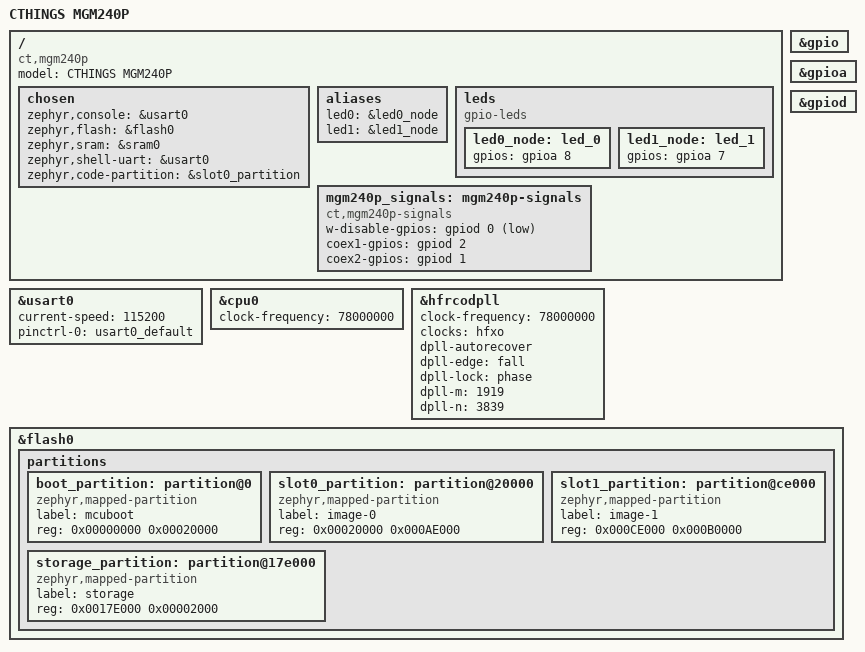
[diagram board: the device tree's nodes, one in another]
#include <silabs/xg24/mgm240pa32vnn.dtsi>
#include <zephyr/dt-bindings/gpio/gpio.h>
#include "mgm240p-pinctrl.dtsi"

/*
 * MGM240P debug interface (common to both card variants):
 *
 * PA1 - SWCLK
 * PA2 - SWDIO
 * PA3 - TRACEDATA0
 * PA4 - TRACECLK
 *
 * These pins are connected to the debug interface.
 * They are documented here but are not configured as GPIOs.
 */


/ {
	model = "CTHINGS MGM240P";
	compatible = "ct,mgm240p", "silabs,efr32mg24";

	chosen {
		zephyr,console = &usart0;
		zephyr,flash = &flash0;
		zephyr,sram = &sram0;
		zephyr,shell-uart = &usart0;
		zephyr,code-partition = &slot0_partition;
	};

	aliases {
		led0 = &led0_node;
		led1 = &led1_node;
	};

	leds {
		compatible = "gpio-leds";

		led0_node: led_0 {
			gpios = <&gpioa 8 GPIO_ACTIVE_HIGH>;
		};

		led1_node: led_1 {
			gpios = <&gpioa 7 GPIO_ACTIVE_HIGH>;
		};
	};

	mgm240p_signals: mgm240p-signals {
		compatible = "ct,mgm240p-signals";

		w-disable-gpios = <&gpiod 0 GPIO_ACTIVE_LOW>;
		coex1-gpios = <&gpiod 2 GPIO_ACTIVE_HIGH>;
		coex2-gpios = <&gpiod 1 GPIO_ACTIVE_HIGH>;
	};
};

&usart0 {
	current-speed = <115200>;
	pinctrl-0 = <&usart0_default>;
	pinctrl-names = "default";
	status = "okay";
};

&gpio {
	status = "okay";
};

&gpioa {
	status = "okay";
};

&gpiod {
	status = "okay";
};

&cpu0 {
	clock-frequency = <78000000>;
};

&hfrcodpll {
	clock-frequency = <78000000>;
	clocks = <&hfxo>;
	dpll-autorecover;
	dpll-edge = "fall";
	dpll-lock = "phase";
	dpll-m = <1919>;
	dpll-n = <3839>;
};

/*
 * Internal flash layout for MCUboot.
 *
 * Total flash: 1536 KiB
 * Erase page: 8 KiB
 *
 * MCUboot: 128 KiB
 * Slot 0: 696 KiB
 * Slot 1: 704 KiB
 * Storage: 8 KiB
 */

&flash0 {
    #address-cells = <1>;
    #size-cells = <1>;
    ranges = <0x00000000 0x08000000 DT_SIZE_K(1536)>;

    partitions {
        ranges;
        #address-cells = <1>;
        #size-cells = <1>;

        boot_partition: partition@0 {
            compatible = "zephyr,mapped-partition";
            label = "mcuboot";
            reg = <0x00000000 0x00020000>;
        };

        slot0_partition: partition@20000 {
            compatible = "zephyr,mapped-partition";
            label = "image-0";
            reg = <0x00020000 0x000AE000>;
        };

        slot1_partition: partition@ce000 {
            compatible = "zephyr,mapped-partition";
            label = "image-1";
            reg = <0x000CE000 0x000B0000>;
        };

        storage_partition: partition@17e000 {
            compatible = "zephyr,mapped-partition";
            label = "storage";
            reg = <0x0017E000 0x00002000>;
        };
    };
};
